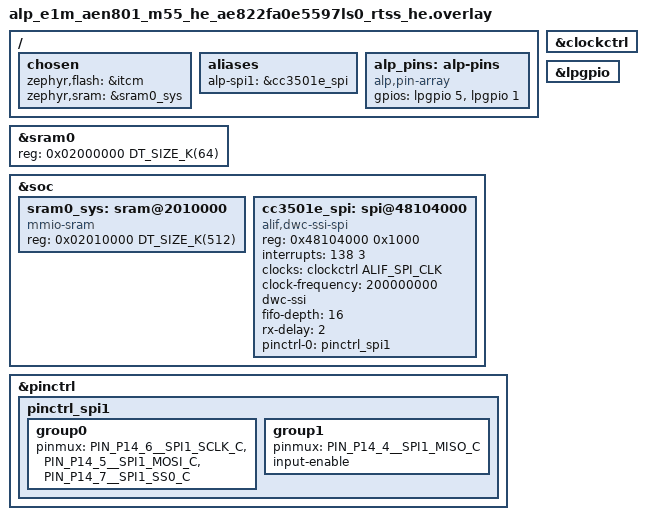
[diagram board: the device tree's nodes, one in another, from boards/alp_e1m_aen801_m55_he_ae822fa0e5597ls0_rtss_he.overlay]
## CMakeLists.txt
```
# SPDX-License-Identifier: Apache-2.0
#
# aen-cc3501e-connect-twice-probe -- tests whether a station-never-associated
# WIFI_DISCONNECT clears the CC3501E vendor SDK's WLAN_IF_DISCONNECT_IN_
# PROGRESS bit (#2035). See src/main.c for the full hypothesis and evidence
# chain.
#
# Standalone Zephyr app (no alp_project.py board.yaml flow), same shape as
# its siblings aen-cc3501e-command-sweep / aen-cc3501e-socket-throughput:
# build with
#   ZEPHYR_BASE=<zephyr-base> west build \
#     -b alp_e1m_aen801_m55_he/ae822fa0e5597ls0/rtss_he <this-dir> -- \
#     "-DEXTRA_ZEPHYR_MODULES=<alp-sdk>;<hal_alif>"
# Zephyr applies boards/<fully-qualified-board>.overlay by itself.

cmake_minimum_required(VERSION 3.20)

find_package(Zephyr REQUIRED HINTS $ENV{ZEPHYR_BASE})
project(aen_cc3501e_connect_twice_probe LANGUAGES C)

target_sources(app PRIVATE src/main.c)
# The SoM bring-up TEMPLATE (see its own header comment): opens the
# inter-chip SPI1 bridge + WIFI_EN/nRESET, enables the LP-pad output
# drivers pinctrl does not reach, binds the READY line, and runs the
# power + reset sequence. Copied verbatim from aen-cc3501e-command-sweep --
# byte-identical to the copies in every other aen-cc3501e-* sibling, same
# reasoning: a copyable template, not a cross-example reach-in.
target_sources(app PRIVATE src/cc3501e_bridge.c)
```

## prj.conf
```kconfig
# SPDX-License-Identifier: Apache-2.0
#
# Bench config for the CC3501E connect-twice probe on the E1M-AEN801 (Alif
# Ensemble E8, M55-HE). See src/main.c for the hypothesis this app tests.

# --- Console -----------------------------------------------------------------
# Console: Alp UART console -- E1M edge UART0 (Alif UART5, P3_4/P3_5, 115200
# 8N1, NS16550), the E1M-AEN801 carrier console. The board _defconfig already
# selects it; set explicitly here so the app is self-describing.
CONFIG_SERIAL=y
CONFIG_CONSOLE=y
CONFIG_UART_CONSOLE=y
CONFIG_UART_INTERRUPT_DRIVEN=y
# Serial-less bench? Comment the four lines above and uncomment these to read
# 'ram_console_buf' over SWD instead -- the same toggle every sibling AEN
# bench app documents (see aen-rtc-tick-probe's prj.conf for the fuller note):
# CONFIG_RAM_CONSOLE=y
# CONFIG_RAM_CONSOLE_BUFFER_SIZE=4096
# CONFIG_UART_CONSOLE=n
CONFIG_PRINTK=y

# --- CC3501E bridge (SPI1 + WIFI_EN/nRESET/READY GPIOs) -----------------------
# The host-side chip driver (chips/cc3501e/*.c) plus the two peripheral
# classes it rides on: SPI for the inter-chip link (bus 1 -> the alp-spi1
# alias this app's overlay adds) and GPIO for WIFI_EN / nRESET / READY.
# Kconfig already enforces `depends on SPI && GPIO`; both are set explicitly
# here because this app has no board.yaml `peripherals:` block to generate
# them -- it is a standalone Zephyr app (see scripts/gen_example_alp_conf.py), same as its
# aen-cc3501e-* siblings. CONFIG_ALP_SDK_CHIP_CC3501E pulls in every
# chips/cc3501e/*.c TU (wifi/sockets/ble/gpio/spi/camera/power/ota/events),
# so this app can call cc3501e_wifi_scan()/cc3501e_wifi_connect()/
# cc3501e_wifi_status()/cc3501e_wifi_disconnect() directly with no further
# Kconfig -- it never routes through the portable <alp/wifi.h> backend
# (CONFIG_ALP_SDK_WIFI_CC3501E), which attaches a DIFFERENT set of TUs this
# app has no use for.
CONFIG_SPI=y
CONFIG_GPIO=y
CONFIG_ALP_SDK=y
CONFIG_ALP_SDK_CHIP_CC3501E=y

# CONFIG_ALP_SDK=y above defaults CONFIG_ALP_SDK_CONSOLE (zephyr/kconfigs/
# core.kconfig) to `y`, which `select`s CONFIG_SHELL -- pulling a `uart:~$`
# shell prompt into the middle of this app's own transcript. This app never
# registers a shell command and never uses the `alp` console tree, so turn
# the console off explicitly rather than let its default drag the shell in
# unasked.
CONFIG_ALP_SDK_CONSOLE=n

# main()'s own cc3501e_t bridge handle (~32 KB, embeds several
# ALP_CC3501E_MAX_PAYLOAD scratch buffers) is STATIC in src/main.c, not
# automatic -- see that file's own header for why that discipline is
# load-bearing here, not optional: a sibling app in this tree died on its own
# prologue for exactly the mistake this app avoids by construction. 4096
# matches every other aen-cc3501e-* sibling that calls this driver with the
# same static discipline and carries no bulk sweep buffers of its own.
CONFIG_MAIN_STACK_SIZE=4096

# Logging ON, deliberately -- a desynced SPI link reports its decisive fault
# via LOG_ERR in the upstream DesignWare SPI driver, and this app is a bench
# diagnostic, not a shipping image. LOG_MODE_MINIMAL keeps it deferred-free.
CONFIG_LOG=y
CONFIG_LOG_MODE_MINIMAL=y

# --- Memory/cache: MATCH aen-cc3501e-command-sweep, not just its pin config --
# CONFIG_DCACHE=n for the SoC-wide reason every AEN801 bench app carries it
# (scripts/bench/aen/aen-bench-shared.conf's own header: "the E8 D-cache
# maintenance loop hangs on this silicon"), AND because this app's PING /
# WIFI_STATUS reads ride the SAME SPI1 link every other AEN801 CC3501E bench
# app measures -- see the app overlay's own header for the matching
# zephyr,sram retarget this depends on.
CONFIG_DCACHE=n
```

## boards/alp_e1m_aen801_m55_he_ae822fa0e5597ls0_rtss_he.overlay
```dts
/*
 * Copyright (c) 2026 Alp Lab AB
 * SPDX-License-Identifier: Apache-2.0
 *
 * aen-cc3501e-connect-twice-probe -- app overlay for the E1M-AEN801 (Alif
 * Ensemble E8, M55-HE), bench RAM-run via J-Link.
 *
 * Byte-identical to aen-cc3501e-command-sweep's own overlay (itself
 * transcribed from aen-evk-demo's phase-8 overlay block -- see that file's
 * own header for the full derivation behind every value here), including
 * the SRAM0 system-RAM placement and CONFIG_DCACHE=n pairing this app does
 * NOT itself need for a throughput reason (it runs no bulk sweep) but keeps
 * anyway: this app's PING and WIFI_STATUS reads ride the identical SPI1
 * link every other AEN801 CC3501E bench app measures, and a
 * faster-than-intended cache/DTCM path would risk a DIFFERENT link timing
 * than the one every sibling's bench evidence was gathered against. Trimmed
 * to exactly what the bridge needs: the SoM-internal Alif <-> CC3501E link
 * (SPI1 hardware SS0, the LP-GPIO island carrying WIFI_EN/nRESET, and the
 * READY input) plus the mandatory bench ITCM retarget. None of
 * aen-evk-demo's other thirteen phases' OWN hardware (PWM LED, SD, Ethernet,
 * I2S/PDM, JPEG) is declared here -- this app touches none of it, and
 * carrying it would only risk a pad conflict with the bridge pins.
 */
#include <zephyr/dt-bindings/pinctrl/alif-ensemble-pinctrl.h>
#include <zephyr/dt-bindings/gpio/gpio.h>

/*
 * ============================================================================
 * SYSTEM-RAM PLACEMENT -- MATCHES aen-evk-demo's phase 8, deliberately
 * ============================================================================
 *
 * This app trims aen-evk-demo's overlay down to exactly the SoM-internal
 * CC3501E bridge (see the block below) -- EXCEPT for this one piece, which
 * it keeps even though nothing else here needs it.
 *
 * aen-evk-demo's own overlay (see ITS header for the full derivation, which
 * this app does not repeat) documents that phase 8's SPI1 FIFO refill --
 * the SAME link this app's Part 2 clocks bulk STREAM_WRITE / SPI1_TRANSFER
 * frames over -- is the one phase sensitive to cache-on vs cache-off timing
 * on this silicon: a DesignWare SSI master that underruns its TX FIFO
 * deasserts its own chip-select mid-frame, and the demo runs from uncached
 * global SRAM0 with CONFIG_DCACHE=n (see prj.conf) rather than the M55's
 * tightly-coupled DTCM specifically to keep that FIFO-refill loop on the
 * same timing this silicon was bench-validated against.
 *
 * A throughput measurement over that link cannot run FASTER than the demo's
 * on precisely the axis the demo's own comment calls out -- that would not
 * be a number anyone else's AEN801 bench run could be compared against, it
 * would be measuring a different link. So this app carries the same
 * retarget, even though (unlike the demo) it has no Ethernet DMA rings or
 * JPEG buffers that need SRAM0 for their own reasons -- one disjoint 512 KiB
 * window is more than this app's own footprint needs, but a narrower
 * carve-out would only add a second constant to keep in sync with the demo
 * for no behavioural benefit.
 */
&sram0 {
	reg = <0x02000000 DT_SIZE_K(64)>;
};

&soc {
	/* Plain "mmio-sram", NOT "zephyr,memory-region" -- see aen-evk-demo's
	 * overlay for why a second memory-region-compatible node here would
	 * alias the linker region instead of extending it. */
	sram0_sys: sram@2010000 {
		compatible = "mmio-sram";
		reg = <0x02010000 DT_SIZE_K(512)>;
	};
};

/*
 * MANDATORY bench RAM-run retarget: run from ITCM so J-Link can loadbin+run
 * without programming MRAM, and drop the MCUboot code-partition fixup.
 * PATH-REFERENCE form (&itcm), NOT the <&itcm> phandle-array form -- the
 * phandle-array form yields CONFIG_FLASH_SIZE=0 and the image overflows the
 * (empty) FLASH region at link time. System RAM (zephyr,sram) is retargeted
 * separately, to &sram0_sys above -- see that block's header.
 */
/ {
	chosen {
		zephyr,flash = &itcm;
		/delete-property/ zephyr,code-partition;
		zephyr,sram = &sram0_sys;
	};
};

/*
 * ============================================================================
 * The SoM-internal Alif <-> CC3501E Wi-Fi/BLE bridge
 * ============================================================================
 *
 *     net          Alif pad       dir   CC3501E pad
 *     ----------   ------------   ---   ---------------------
 *     WIFI_EN      P15_5          out   (supply gate)
 *     E_WIFI.NRST  P15_1_FLEX     out   (reset)
 *     SPI1.SCK     P14_6          out   GPIO_27 (CC35 SPI0 slave)
 *     SPI1.MOSI    P14_5          out   GPIO_28
 *     SPI1.MISO    P14_4          in    GPIO_29
 *     SPI1.SS0     P14_7          out   CC35 SPI0 CSN
 *
 * READY (CC35 GPIO_17) is deliberately left off this table: on the R2
 * module this app targets it is NOT wired to Alif P2_6 -- P2_6 is E1M pad
 * AH7 / I2S1_SCLK (the EVK's Arduino CK_RST), a DIFFERENT net from GPIO_17
 * / E1M pad G3.  See the P2_6 comment further down and
 * chips/cc3501e/cc3501e_core.c's cc3501e_reply_gate() comment for the bench
 * evidence and how a board that genuinely wires it can opt in.
 *
 * SoM-INTERNAL fact (metadata/e1m_modules/aen/inter-chip.tsv), not an E1M
 * edge pad -- hence an app overlay, not the board tree.
 */
&pinctrl {
	/*
	 * SPI1 master on P14_6 (SCK) / P14_5 (MOSI) / P14_4 (MISO), plus the
	 * hardware SS0 chip-select on P14_7. SS0 is the dwc-ssi peripheral's
	 * OWN select -- not a GPIO bodge, not CS-less, not static-low: the
	 * master asserts and deasserts it per transfer, which is exactly what
	 * frames each phase of the bridge's request/reply exchange. Do NOT
	 * add cs-gpios here; that installs a software CS and breaks the
	 * framing the firmware side is built around.
	 *
	 * input-enable on MISO because on this SoC a pad's INPUT BUFFER is a
	 * PADCTRL bit that only pinctrl sets -- without it the pad never
	 * senses what the slave drives.
	 */
	pinctrl_spi1: pinctrl_spi1 {
		group0 {
			pinmux = <PIN_P14_6__SPI1_SCLK_C>, <PIN_P14_5__SPI1_MOSI_C>,
				 <PIN_P14_7__SPI1_SS0_C>;
		};
		group1 {
			pinmux = <PIN_P14_4__SPI1_MISO_C>;
			input-enable;
		};

	};
};

/* P2_6 (E1M AH7 / I2S1_SCLK) is NOT the CC3501E READY net on the R2 module this
 * bridge targets -- it is E1M pad AH7 / I2S1_SCLK, which the E1M EVK
 * carrier repurposes as the Arduino header's CK_RST (metadata/boards/
 * e1m-evk.yaml); the real READY net lands on E1M pad G3 / IO16 instead
 * (metadata/e1m_modules/aen/from-cc3501e.tsv). This app therefore does not
 * mux or input-enable P2_6, and does not wire fw->ready_pin -- see
 * src/cc3501e_bridge.c and chips/cc3501e/cc3501e_core.c's cc3501e_reply_gate()
 * comment. A board (or a hand-reworked r1 unit) that genuinely wires GPIO17
 * to P2_6 can opt back in: add a pinctrl group muxing PIN_P2_6__GPIO with
 * input-enable (applied inside pinctrl_spi1's single init pass, not a
 * standalone runtime one -- a second pinctrl pass after SPI1 is up killed
 * the bridge on silicon, aen-evk-demo bench-measured), enable &gpio2, add
 * an alp_pins entry for it, and set fw->ready_pin in
 * cc3501e_bridge_bringup().

/*
 * DWC_ssi SPI1 (AHB) -- the on-SoM CC3501E inter-chip link. Deliberately not
 * in ensemble_e8_peripherals.dtsi (which declares only the customer-facing
 * edge SPI0), so the consuming app declares it. reg 0x48104000 = the SPI1
 * base (+0x1000 per instance from spi0's 0x48103000).
 *
 * clock-frequency is REQUIRED, not decorative: without it spi_dw_alif's
 * configure takes the clock-control path, which fails -EINVAL for the
 * gateless dummy ALIF_SPI_CLK, and every transceive then returns
 * ALP_ERR_INVAL at zero SCLK. 200 MHz is the real SSI functional clock (E8
 * HWRM); BAUDR = clock-frequency / freq_hz, and cc3501e_bridge.h asks for
 * 25 MHz = /8.
 *
 * rx-delay: NOT what clocks the link -- src/cc3501e_bridge.c pokes
 * 0x48104000+0xf0 with CC3501E_BRIDGE_RX_SAMPLE_DLY right after
 * alp_spi_open() returns, and that constant (silicon-measured, see that
 * file's header) is what the bridge actually runs at. Kept at <2> anyway
 * because the poke is wrapped in `#if CC3501E_BRIDGE_RX_SAMPLE_DLY > 0` --
 * setting the constant to 0 does not mean "no delay", it means this
 * property is what survives.
 */
&clockctrl {
	status = "okay";
};

&soc {
	cc3501e_spi: spi@48104000 {
		compatible = "alif,dwc-ssi-spi";
		#address-cells = <1>;
		#size-cells = <0>;
		reg = <0x48104000 0x1000>;
		interrupts = <138 3>; /* BENCH-TBD: confirm SPI1 IRQ, same as aen-evk-demo */
		clocks = <&clockctrl ALIF_SPI_CLK>;
		clock-frequency = <200000000>;
		dwc-ssi;
		fifo-depth = <16>;
		rx-delay = <2>;
		pinctrl-0 = <&pinctrl_spi1>;
		pinctrl-names = "default";
		status = "okay";
	};
};

/*
 * The LP-GPIO island carries WIFI_EN (P15_5) and E_WIFI.NRST (P15_1_FLEX).
 * No pinctrl group is needed for their mux: P15_x function 0 -- the reset
 * default -- already IS LPGPIO. Turning the pads' OUTPUT DRIVERS on is a
 * separate matter and not a devicetree fact at all; see the raw PADCTRL
 * write in src/cc3501e_bridge.c and the comment above it.
 */
&lpgpio {
	status = "okay";
};

/ {
	aliases {
		/* bus_id 1 in alp_spi_open() -> this controller. */
		alp-spi1 = &cc3501e_spi;
	};

	/*
	 * Compact 2-entry control array for the SoM-internal CC3501E control
	 * nets, in the order cc3501e_bridge.h's CC3501E_BRIDGE_PIN_* indices
	 * expect. These are NOT E1M edge pads, so this app does not use the
	 * 52-slot positional E1M map; a production board file appends
	 * SoM-internal control nets after the E1M pad slots. No READY entry
	 * here -- see the P2_6 comment above &gpio2's removal further up.
	 *
	 * There must be exactly ONE "alp,pin-array" node in the tree -- a
	 * second one broke pin resolution outright on the aen-evk-demo bench
	 * (2026-08-26): the bridge failed as if WIFI_EN were absent, which
	 * reads like a hardware fault and is not one.
	 */
	alp_pins: alp-pins {
		compatible = "alp,pin-array";
		gpios = <&lpgpio 5 GPIO_ACTIVE_HIGH>, /* [0] WIFI_EN     (P15_5)      */
			<&lpgpio 1 GPIO_ACTIVE_HIGH>; /* [1] E_WIFI.NRST (P15_1_FLEX) */
	};
};
```

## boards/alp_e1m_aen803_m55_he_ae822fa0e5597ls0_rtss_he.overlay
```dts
/*
 * Copyright (c) 2026 Alp Lab AB
 * SPDX-License-Identifier: Apache-2.0
 *
 * aen-cc3501e-connect-twice-probe -- app overlay for the E1M-AEN803 (Alif
 * Ensemble E8, M55-HE), bench RAM-run via J-Link.
 *
 * Byte-identical to aen-cc3501e-command-sweep's own overlay (itself
 * transcribed from aen-evk-demo's phase-8 overlay block -- see that file's
 * own header for the full derivation behind every value here), including
 * the SRAM0 system-RAM placement and CONFIG_DCACHE=n pairing this app does
 * NOT itself need for a throughput reason (it runs no bulk sweep) but keeps
 * anyway: this app's PING and WIFI_STATUS reads ride the identical SPI1
 * link every other AEN803 CC3501E bench app measures, and a
 * faster-than-intended cache/DTCM path would risk a DIFFERENT link timing
 * than the one every sibling's bench evidence was gathered against. Trimmed
 * to exactly what the bridge needs: the SoM-internal Alif <-> CC3501E link
 * (SPI1 hardware SS0, the LP-GPIO island carrying WIFI_EN/nRESET, and the
 * READY input) plus the mandatory bench ITCM retarget. None of
 * aen-evk-demo's other thirteen phases' OWN hardware (PWM LED, SD, Ethernet,
 * I2S/PDM, JPEG) is declared here -- this app touches none of it, and
 * carrying it would only risk a pad conflict with the bridge pins.
 */
#include <zephyr/dt-bindings/pinctrl/alif-ensemble-pinctrl.h>
#include <zephyr/dt-bindings/gpio/gpio.h>

/*
 * ============================================================================
 * SYSTEM-RAM PLACEMENT -- MATCHES aen-evk-demo's phase 8, deliberately
 * ============================================================================
 *
 * This app trims aen-evk-demo's overlay down to exactly the SoM-internal
 * CC3501E bridge (see the block below) -- EXCEPT for this one piece, which
 * it keeps even though nothing else here needs it.
 *
 * aen-evk-demo's own overlay (see ITS header for the full derivation, which
 * this app does not repeat) documents that phase 8's SPI1 FIFO refill --
 * the SAME link this app's Part 2 clocks bulk STREAM_WRITE / SPI1_TRANSFER
 * frames over -- is the one phase sensitive to cache-on vs cache-off timing
 * on this silicon: a DesignWare SSI master that underruns its TX FIFO
 * deasserts its own chip-select mid-frame, and the demo runs from uncached
 * global SRAM0 with CONFIG_DCACHE=n (see prj.conf) rather than the M55's
 * tightly-coupled DTCM specifically to keep that FIFO-refill loop on the
 * same timing this silicon was bench-validated against.
 *
 * A throughput measurement over that link cannot run FASTER than the demo's
 * on precisely the axis the demo's own comment calls out -- that would not
 * be a number anyone else's AEN803 bench run could be compared against, it
 * would be measuring a different link. So this app carries the same
 * retarget, even though (unlike the demo) it has no Ethernet DMA rings or
 * JPEG buffers that need SRAM0 for their own reasons -- one disjoint 512 KiB
 * window is more than this app's own footprint needs, but a narrower
 * carve-out would only add a second constant to keep in sync with the demo
 * for no behavioural benefit.
 */
&sram0 {
	reg = <0x02000000 DT_SIZE_K(64)>;
};

&soc {
	/* Plain "mmio-sram", NOT "zephyr,memory-region" -- see aen-evk-demo's
	 * overlay for why a second memory-region-compatible node here would
	 * alias the linker region instead of extending it. */
	sram0_sys: sram@2010000 {
		compatible = "mmio-sram";
		reg = <0x02010000 DT_SIZE_K(512)>;
	};
};

/*
 * MANDATORY bench RAM-run retarget: run from ITCM so J-Link can loadbin+run
 * without programming MRAM, and drop the MCUboot code-partition fixup.
 * PATH-REFERENCE form (&itcm), NOT the <&itcm> phandle-array form -- the
 * phandle-array form yields CONFIG_FLASH_SIZE=0 and the image overflows the
 * (empty) FLASH region at link time. System RAM (zephyr,sram) is retargeted
 * separately, to &sram0_sys above -- see that block's header.
 */
/ {
	chosen {
		zephyr,flash = &itcm;
		/delete-property/ zephyr,code-partition;
		zephyr,sram = &sram0_sys;
	};
};

/*
 * ============================================================================
 * The SoM-internal Alif <-> CC3501E Wi-Fi/BLE bridge
 * ============================================================================
 *
 *     net          Alif pad       dir   CC3501E pad
 *     ----------   ------------   ---   ---------------------
 *     WIFI_EN      P15_5          out   (supply gate)
 *     E_WIFI.NRST  P15_1_FLEX     out   (reset)
 *     SPI1.SCK     P14_6          out   GPIO_27 (CC35 SPI0 slave)
 *     SPI1.MOSI    P14_5          out   GPIO_28
 *     SPI1.MISO    P14_4          in    GPIO_29
 *     SPI1.SS0     P14_7          out   CC35 SPI0 CSN
 *
 * READY (CC35 GPIO_17) is deliberately left off this table: on the R2
 * module this app targets it is NOT wired to Alif P2_6 -- P2_6 is E1M pad
 * AH7 / I2S1_SCLK (the EVK's Arduino CK_RST), a DIFFERENT net from GPIO_17
 * / E1M pad G3.  See the P2_6 comment further down and
 * chips/cc3501e/cc3501e_core.c's cc3501e_reply_gate() comment for the bench
 * evidence and how a board that genuinely wires it can opt in.
 *
 * SoM-INTERNAL fact (metadata/e1m_modules/aen/inter-chip.tsv), not an E1M
 * edge pad -- hence an app overlay, not the board tree.
 */
&pinctrl {
	/*
	 * SPI1 master on P14_6 (SCK) / P14_5 (MOSI) / P14_4 (MISO), plus the
	 * hardware SS0 chip-select on P14_7. SS0 is the dwc-ssi peripheral's
	 * OWN select -- not a GPIO bodge, not CS-less, not static-low: the
	 * master asserts and deasserts it per transfer, which is exactly what
	 * frames each phase of the bridge's request/reply exchange. Do NOT
	 * add cs-gpios here; that installs a software CS and breaks the
	 * framing the firmware side is built around.
	 *
	 * input-enable on MISO because on this SoC a pad's INPUT BUFFER is a
	 * PADCTRL bit that only pinctrl sets -- without it the pad never
	 * senses what the slave drives.
	 */
	pinctrl_spi1: pinctrl_spi1 {
		group0 {
			pinmux = <PIN_P14_6__SPI1_SCLK_C>, <PIN_P14_5__SPI1_MOSI_C>,
				 <PIN_P14_7__SPI1_SS0_C>;
		};
		group1 {
			pinmux = <PIN_P14_4__SPI1_MISO_C>;
			input-enable;
		};

	};
};

/* P2_6 (E1M AH7 / I2S1_SCLK) is NOT the CC3501E READY net on the R2 module this
 * bridge targets -- it is E1M pad AH7 / I2S1_SCLK, which the E1M EVK
 * carrier repurposes as the Arduino header's CK_RST (metadata/boards/
 * e1m-evk.yaml); the real READY net lands on E1M pad G3 / IO16 instead
 * (metadata/e1m_modules/aen/from-cc3501e.tsv). This app therefore does not
 * mux or input-enable P2_6, and does not wire fw->ready_pin -- see
 * src/cc3501e_bridge.c and chips/cc3501e/cc3501e_core.c's cc3501e_reply_gate()
 * comment. A board (or a hand-reworked r1 unit) that genuinely wires GPIO17
 * to P2_6 can opt back in: add a pinctrl group muxing PIN_P2_6__GPIO with
 * input-enable (applied inside pinctrl_spi1's single init pass, not a
 * standalone runtime one -- a second pinctrl pass after SPI1 is up killed
 * the bridge on silicon, aen-evk-demo bench-measured), enable &gpio2, add
 * an alp_pins entry for it, and set fw->ready_pin in
 * cc3501e_bridge_bringup().

/*
 * DWC_ssi SPI1 (AHB) -- the on-SoM CC3501E inter-chip link. Deliberately not
 * in ensemble_e8_peripherals.dtsi (which declares only the customer-facing
 * edge SPI0), so the consuming app declares it. reg 0x48104000 = the SPI1
 * base (+0x1000 per instance from spi0's 0x48103000).
 *
 * clock-frequency is REQUIRED, not decorative: without it spi_dw_alif's
 * configure takes the clock-control path, which fails -EINVAL for the
 * gateless dummy ALIF_SPI_CLK, and every transceive then returns
 * ALP_ERR_INVAL at zero SCLK. 200 MHz is the real SSI functional clock (E8
 * HWRM); BAUDR = clock-frequency / freq_hz, and cc3501e_bridge.h asks for
 * 25 MHz = /8.
 *
 * rx-delay: NOT what clocks the link -- src/cc3501e_bridge.c pokes
 * 0x48104000+0xf0 with CC3501E_BRIDGE_RX_SAMPLE_DLY right after
 * alp_spi_open() returns, and that constant (silicon-measured, see that
 * file's header) is what the bridge actually runs at. Kept at <2> anyway
 * because the poke is wrapped in `#if CC3501E_BRIDGE_RX_SAMPLE_DLY > 0` --
 * setting the constant to 0 does not mean "no delay", it means this
 * property is what survives.
 */
&clockctrl {
	status = "okay";
};

&soc {
	cc3501e_spi: spi@48104000 {
		compatible = "alif,dwc-ssi-spi";
		#address-cells = <1>;
		#size-cells = <0>;
		reg = <0x48104000 0x1000>;
		interrupts = <138 3>; /* BENCH-TBD: confirm SPI1 IRQ, same as aen-evk-demo */
		clocks = <&clockctrl ALIF_SPI_CLK>;
		clock-frequency = <200000000>;
		dwc-ssi;
		fifo-depth = <16>;
		rx-delay = <2>;
		pinctrl-0 = <&pinctrl_spi1>;
		pinctrl-names = "default";
		status = "okay";
	};
};

/*
 * The LP-GPIO island carries WIFI_EN (P15_5) and E_WIFI.NRST (P15_1_FLEX).
 * No pinctrl group is needed for their mux: P15_x function 0 -- the reset
 * default -- already IS LPGPIO. Turning the pads' OUTPUT DRIVERS on is a
 * separate matter and not a devicetree fact at all; see the raw PADCTRL
 * write in src/cc3501e_bridge.c and the comment above it.
 */
&lpgpio {
	status = "okay";
};

/ {
	aliases {
		/* bus_id 1 in alp_spi_open() -> this controller. */
		alp-spi1 = &cc3501e_spi;
	};

	/*
	 * Compact 2-entry control array for the SoM-internal CC3501E control
	 * nets, in the order cc3501e_bridge.h's CC3501E_BRIDGE_PIN_* indices
	 * expect. These are NOT E1M edge pads, so this app does not use the
	 * 52-slot positional E1M map; a production board file appends
	 * SoM-internal control nets after the E1M pad slots. No READY entry
	 * here -- see the P2_6 comment above &gpio2's removal further up.
	 *
	 * There must be exactly ONE "alp,pin-array" node in the tree -- a
	 * second one broke pin resolution outright on the aen-evk-demo bench
	 * (2026-08-26): the bridge failed as if WIFI_EN were absent, which
	 * reads like a hardware fault and is not one.
	 */
	alp_pins: alp-pins {
		compatible = "alp,pin-array";
		gpios = <&lpgpio 5 GPIO_ACTIVE_HIGH>, /* [0] WIFI_EN     (P15_5)      */
			<&lpgpio 1 GPIO_ACTIVE_HIGH>; /* [1] E_WIFI.NRST (P15_1_FLEX) */
	};
};
```

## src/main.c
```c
/*
 * Copyright (c) 2026 Alp Lab AB
 * SPDX-License-Identifier: Apache-2.0
 *
 * aen-cc3501e-connect-twice-probe -- tests whether a WIFI_DISCONNECT issued
 * against a station that never associated clears the CC3501E vendor SDK's
 * WLAN_IF_DISCONNECT_IN_PROGRESS bit, for the E1M-AEN801 (Alif Ensemble E8,
 * M55-HE), bench RAM-run via J-Link.
 *
 * THE CHAIN THIS APP TESTS
 * ---------------------------
 * Read from the TI vendor SDK sources directly
 * (source/ti/net/wifi_stack/app_entry/wlan_if.c and .../cme/cme.c,
 * simplelink_wifi_sdk_10_10_01_08), not inferred:
 *
 *   1. Wlan_Disconnect() calls set_cond_in_process_wlan_discconnect(1),
 *      which sets WLAN_IF_DISCONNECT_IN_PROGRESS in the SDK's own
 *      g_oper_bitmap.
 *   2. On the STATION branch (the `default:` case of Wlan_Disconnect()'s
 *      switch, which is what a plain STA disconnect always takes) it
 *      returns WITHOUT clearing that bit -- only the AP branch and the
 *      `fail:` label clear it inline. Read the function yourself before
 *      touching this file: the station path's own `else { return ret; }`
 *      is the whole defect surface.
 *   3. The only other place that clears it is the WLAN_EVENT_DISCONNECT
 *      handler (cme.c, wlanDispatcherSendEvent(WLAN_EVENT_DISCONNECT, ...)).
 *   4. Wlan_Connect() gates on the SAME bitmap via
 *      set_cond_in_process_wlan_connect() -> is_wlan_oper_in_progress(),
 *      whose allow-mask for CONNECT is
 *      ROLE_UP_AP | ROLE_DOWN_AP | SET | GET | GET_EXCLUDE | SET_EXCLUDE.
 *      WLAN_IF_DISCONNECT_IN_PROGRESS is NOT in that mask.
 *   5. So while that bit stays set, every Wlan_Connect returns
 *      RET_OPER_IN_PROGRESS immediately -- which the bridge firmware maps
 *      to ALP_CC3501E_WIFI_FAIL_KICK.
 *
 * THE ONE UNPROVEN LINK -- and the only thing this app exists to test:
 * whether the supplicant emits WLAN_EVENT_DISCONNECT when asked to
 * disconnect a station that never associated. If it does, the bit clears
 * (mechanism 3 above fires) and none of this bites. If it does NOT, the bit
 * sticks for the rest of the session and every later connect dies at the
 * kick (mechanism 5).
 *
 * WHY THIS APP CAN OBSERVE THAT WITHOUT READING FIRMWARE STATE DIRECTLY:
 * cc3501e_wifi_connect() (chips/cc3501e/cc3501e_wifi.c) already issues a
 * WIFI_DISCONNECT at ENTRY whenever the WIFI_STATUS latch reads
 * CONN_FAILED from a previous attempt -- see that function's own #1435
 * comment. THAT disconnect is itself the call that would set the bit in
 * the first place if attempt one never associated. Attempt two's entry
 * clear is therefore exactly the real path this app exists to exercise --
 * do NOT try to bypass it or call cc3501e_wifi_disconnect() directly
 * around it; the whole point is to let cc3501e_wifi_connect()'s own,
 * already-shipped, entry-clear logic run twice back to back.
 *
 * WHY SCAN FIRST -- load-bearing, not decoration
 * --------------------------------------------------
 * On the scan-first ordering the link survives a failed connect --
 * measured 2 of 2 in a firmware-side A/B, NOT by any app in this tree --
 * no example here issues a scan before a connect, so do not go looking
 * for the run that produced it. Connect-first wedges it and nothing
 * afterwards can be
 * read. Without the scan this app cannot report anything at all: STEP 3
 * below runs cc3501e_wifi_scan() and prints the record count BEFORE either
 * connect attempt, precisely because skipping it would risk losing the
 * WIFI_STATUS reads that are this app's entire payload.
 *
 * THE PREDICTION -- so the operator does not have to hold it in their head
 * ------------------------------------------------------------------------
 * If attempt one reports FAIL_TIMEOUT and attempt two reports FAIL_KICK,
 * the bit sticks and the hypothesis is CONFIRMED. If both report the SAME
 * reason, it does not stick and the hypothesis is DEAD. If attempt one
 * SUCCEEDS, this run says nothing about any of this -- there was no
 * failure to leave the bit set behind in the first place. STEP 6 below
 * prints exactly this and nothing more; the reasoning belongs to whoever
 * reads the transcript, not to this app.
 *
 * SECURITY VALUE ON THE WIRE -- do not mix the two encodings up
 * --------------------------------------------------------------
 * cc3501e_wifi_connect()'s own `sec_type` parameter goes on the wire as
 * <alp/protocol/cc3501e.h>'s alp_cc3501e_wifi_connect_t::security field:
 * 0 = open, 1 = WPA2-PSK, 2 = WPA3-SAE (CC3501E_WIFI_CONNECT_SEC_OPEN /
 * _WPA2_PSK / _WPA3_SAE in <alp/chips/cc3501e/wifi.h>). This is a DIFFERENT
 * encoding from the scan-RESULT security enum in that same header
 * (cc3501e_wifi_sec_t), where 1 means WEP -- this app never touches that
 * second enum (it only prints scan record COUNT, not per-record security),
 * but a reader porting this pattern elsewhere should not conflate the two.
 *
 * CREDENTIALS -- never committed
 * ---------------------------------
 * Build-time defines, empty defaults, this app's OWN macro prefix
 * (CONNTWICE_*) so a combined build cannot collide with
 * aen-cc3501e-companion-tour's TOUR_*, aen-cc3501e-socket-throughput's
 * SOCKTP_*, aen-cc3501e-bringup's CC3501E_WIFI_*, or
 * aen-cc3501e-wedge-postmortem's WEDGEPM_*. No SSID or passphrase is
 * embedded anywhere in this file. When CONNTWICE_WIFI_SSID is empty, main()
 * says so and stops before either connect attempt runs -- there would be
 * nothing to disconnect and nothing to observe.
 *
 * WHAT THIS APP NEVER DOES
 * ---------------------------
 * Never OTA_*, never RESET, never a soft-AP -- the only opcodes this file
 * issues are WIFI_SCAN_START (via cc3501e_wifi_scan(), STEP 3),
 * WIFI_CONNECT_STA (via cc3501e_wifi_connect(), STEPs 4 and 5, which itself
 * issues WIFI_DISCONNECT at entry when required -- see above), and
 * WIFI_STATUS (via cc3501e_wifi_status(), read after each attempt). Never
 * runs hardware beyond the bench RAM-run this file's own header line names.
 *
 * Build target: alp_e1m_aen801_m55_he/ae822fa0e5597ls0/rtss_he -- same
 * overlay memory placement and CONFIG_DCACHE=n as
 * aen-cc3501e-command-sweep; see this app's README.md for the full west
 * build invocation and that sibling's overlay for why the memory placement
 * is load-bearing, not decorative.
 */

#include <stdbool.h>
#include <stdint.h>

#include <zephyr/kernel.h>

#include "alp/chips/cc3501e.h"
#include "cc3501e_bridge.h" /* cc3501e_bridge_bringup() -- the SoM bring-up template */

/*
 * ======================================================================
 * Tunables -- timeouts and the (build-time) Wi-Fi credentials the file
 * header above explains.
 * ======================================================================
 */

/* Same shape and reasoning as every aen-cc3501e-* sibling's own PING retry
 * loop (e.g. aen-cc3501e-socket-throughput's SOCKTP_PING_RETRIES): the
 * bring-up call already waited out its own boot budget once, so this loop
 * only absorbs residual ramp/boot jitter. */
#define CONNTWICE_PING_RETRIES 25u
#define CONNTWICE_PING_GAP_MS  200u

/* Floored internally to 20 s by cc3501e_wifi_scan() regardless (see that
 * function's own doc) -- this asks for a little more so the literal here
 * means what it says rather than being silently corrected, same reasoning
 * as aen-cc3501e-command-sweep's identical 25 s scan budget. */
#define CONNTWICE_SCAN_TIMEOUT_MS 25000u

/* Full connect budget, NOT a shortened one -- unlike
 * aen-cc3501e-wedge-postmortem's deliberately-shrunk WEDGEPM_CONNECT_
 * TIMEOUT_MS (that app wants to catch the link mid-wedge; this app wants
 * each attempt to reach a genuine TERMINAL WIFI_STATUS so the fail_reason
 * pair it reports is real, not an artifact of giving up early). Same
 * derivation as aen-cc3501e-socket-throughput's SOCKTP_CONNECT_TIMEOUT_MS:
 * the firmware's own worst case is a 10 s Wlan_RoleUp inside the connect body
 * (this image never calls cc3501e_hw_wifi_boot_start, so the first radio op of
 * a boot carries it) + 30 s L2 association + a 30 s DHCP-lease poll
 * (hal/ti/cc3501e_hw_ti_wifi.c) = 70 s, and the firmware documents 75000 ms
 * as the caller budget that clears it (alp-sdk#2079). A connect that gives
 * up early cannot tell a stuck disconnect bit from an impatient caller, and
 * telling those apart is the entire point of the app. */
#define CONNTWICE_CONNECT_TIMEOUT_MS 75000u

/*
 * Wi-Fi STA credentials for both connect attempts. DELIBERATELY EMPTY by
 * default -- never hardcode bench credentials in a public example. Set
 * them at build time WITHOUT editing this file, e.g.:
 *
 *   west build ... -- -DEXTRA_CFLAGS="-DCONNTWICE_WIFI_SSID=\\\"myssid\\\" \
 *                                     -DCONNTWICE_WIFI_PASS=\\\"mypass\\\""
 *
 * When CONNTWICE_WIFI_SSID is empty, main() prints one line saying so and
 * returns before STEP 3 (the scan) even runs -- there is nothing to
 * connect twice, so there is nothing for this app to observe.
 */
#ifndef CONNTWICE_WIFI_SSID
#define CONNTWICE_WIFI_SSID ""
#endif
#ifndef CONNTWICE_WIFI_PASS
#define CONNTWICE_WIFI_PASS ""
#endif
/* Security selector on the WIRE encoding: 0 = open, 1 = WPA2-PSK,
 * 2 = WPA3-SAE (CC3501E_WIFI_CONNECT_SEC_* in <alp/chips/cc3501e/wifi.h>) --
 * see the file header's SECURITY VALUE note for why this is NOT the same
 * numbering as the scan-result security enum. */
#ifndef CONNTWICE_WIFI_SECURITY
#define CONNTWICE_WIFI_SECURITY CC3501E_WIFI_CONNECT_SEC_WPA2_PSK
#endif

/** @brief Human name for an @ref alp_cc3501e_wifi_conn_state_t value. */
static const char *conntwice_state_name(uint8_t state)
{
	switch (state) {
	case ALP_CC3501E_WIFI_DISCONNECTED:
		return "DISCONNECTED";
	case ALP_CC3501E_WIFI_CONNECTING:
		return "CONNECTING";
	case ALP_CC3501E_WIFI_CONNECTED:
		return "CONNECTED";
	case ALP_CC3501E_WIFI_CONN_FAILED:
		return "CONN_FAILED";
	default:
		return "UNKNOWN";
	}
}

/** @brief Human name for an @ref alp_cc3501e_wifi_fail_t value. */
static const char *conntwice_fail_name(uint8_t fail_reason)
{
	switch (fail_reason) {
	case ALP_CC3501E_WIFI_FAIL_NONE:
		return "FAIL_NONE";
	case ALP_CC3501E_WIFI_FAIL_TIMEOUT:
		return "FAIL_TIMEOUT";
	case ALP_CC3501E_WIFI_FAIL_REJECTED:
		return "FAIL_REJECTED";
	case ALP_CC3501E_WIFI_FAIL_KICK:
		return "FAIL_KICK";
	default:
		return "UNKNOWN";
	}
}

/**
 * @brief Run one WIFI_CONNECT_STA attempt and report the terminal WIFI_STATUS.
 *
 * Deliberately does NOT return a bare @c alp_status_t from
 * cc3501e_wifi_connect() as this app's verdict -- that return code collapses
 * TIMEOUT vs REJECTED vs KICK into two bare error codes (see the file
 * header). The independent @ref cc3501e_wifi_status read after it is what
 * this app actually cares about.
 *
 * @param fw          Initialised bridge handle.
 * @param attempt_no  1 or 2, for the printed labels only.
 * @param status_out  Receives the decoded WIFI_STATUS snapshot (zeroed if
 *                     the status read itself failed).
 * @return The @ref cc3501e_wifi_status return code -- ALP_OK if @p status_out
 *         is valid, otherwise the status read's own error.
 */
static alp_status_t
conntwice_attempt(cc3501e_t *fw, unsigned attempt_no, alp_cc3501e_wifi_status_t *status_out)
{
	printk("\nSTEP %u: CONNECT attempt %u -> SSID \"%s\" (sec %u)...\n",
	       3u + attempt_no,
	       attempt_no,
	       CONNTWICE_WIFI_SSID,
	       (unsigned)CONNTWICE_WIFI_SECURITY);

	int64_t      t0 = k_uptime_get();
	alp_status_t rc = cc3501e_wifi_connect(fw,
	                                       CONNTWICE_WIFI_SSID,
	                                       (uint8_t)CONNTWICE_WIFI_SECURITY,
	                                       CONNTWICE_WIFI_PASS,
	                                       CONNTWICE_CONNECT_TIMEOUT_MS);
	int64_t      dt = k_uptime_get() - t0;
	printk("  cc3501e_wifi_connect() -> %d (elapsed_ms=%lld) -- this bare return code alone"
	       " collapses TIMEOUT/REJECTED/KICK; see WIFI_STATUS below for the real reason.\n",
	       (int)rc,
	       (long long)dt);

	alp_cc3501e_wifi_status_t st = { 0 };
	alp_status_t              sr = cc3501e_wifi_status(fw, &st);
	if (sr == ALP_OK) {
		printk("  WIFI_STATUS -> state=%u (%s)  fail_reason=%u (%s)\n",
		       (unsigned)st.state,
		       conntwice_state_name(st.state),
		       (unsigned)st.fail_reason,
		       conntwice_fail_name(st.fail_reason));
	} else {
		printk("  WIFI_STATUS read FAILED (rc=%d) -- state/fail_reason UNREAD for this"
		       " attempt.\n",
		       (int)sr);
	}
	if (status_out != NULL) {
		*status_out = st;
	}
	return sr;
}

/* ---------------------------------------------------------------------- */

int main(void)
{
	printk("\n=== AEN801 CC3501E connect-twice probe (#2035) ===\n");

	/*
	 * STATIC, explicitly zero-initialised cc3501e_t -- same discipline as
	 * every aen-cc3501e-* sibling, for the identical reason: this type
	 * embeds several ALP_CC3501E_MAX_PAYLOAD scratch buffers (~32 KB
	 * total). Declared automatic it asks main() for a multi-kilobyte
	 * stack frame, and Zephyr's stack-overflow check fires on the very
	 * first `sub sp` -- before this function's own first printk, so the
	 * app dies with no output at all and looks like a dead board. That is
	 * not hypothetical: it happened on the M55-HE 2026-09-10 and cost a
	 * bench run (see aen-cc3501e-handshake-probe's own prj.conf).
	 */
	static cc3501e_t fw = { 0 };

	/*
	 * ---------------------------------------------------------------
	 * STEP 1 -- bring the bridge up, byte-identical to aen-evk-demo
	 * phase 8 and every aen-cc3501e-* sibling (same
	 * src/cc3501e_bridge.{c,h} template, same overlay).
	 * ---------------------------------------------------------------
	 */
	alp_status_t rc = cc3501e_bridge_bringup(&fw);
	printk("STEP 1: bridge bring-up (WIFI_EN high, nRESET pulsed, SPI1 @ %u Hz) -> %d\n",
	       (unsigned)CC3501E_BRIDGE_SPI_FREQ_HZ,
	       (int)rc);
	if (rc != ALP_OK) {
		printk("  ** bring-up did NOT return ALP_OK -- nothing downstream of it can work."
		       " Stopping here. **\n");
		return 0;
	}

	/*
	 * ---------------------------------------------------------------
	 * STEP 2 -- confirm the link answers before spending a scan/connect
	 * budget on it. Same retry shape as aen-cc3501e-socket-throughput's
	 * own STEP 2.
	 * ---------------------------------------------------------------
	 */
	bool up = false;
	for (unsigned i = 0u; i < CONNTWICE_PING_RETRIES; i++) {
		if (cc3501e_ping(&fw) == ALP_OK) {
			printk("STEP 2: PING ok after %u attempt%s\n", i + 1u, (i == 0u) ? "" : "s");
			up = true;
			break;
		}
		k_msleep(CONNTWICE_PING_GAP_MS);
	}
	if (!up) {
		printk("STEP 2: PING never answered -- check WIFI_EN power, the SPI1 pinmux, and"
		       " that the CC3501E is running its firmware. Stopping here.\n");
		return 0;
	}

	if (CONNTWICE_WIFI_SSID[0] == '\0') {
		printk("\nNo SSID configured (CONNTWICE_WIFI_SSID empty -- set it at build time,"
		       " see this file's header). Nothing to connect twice, nothing to observe."
		       " Stopping here.\n");
		return 0;
	}

	/*
	 * ---------------------------------------------------------------
	 * STEP 3 -- scan FIRST. Load-bearing, not decoration: on the
	 * scan-first ordering the link survives a failed connect (measured,
	 * 2 of 2); connect-first wedges it and nothing afterwards can be
	 * read. See the file header's WHY SCAN FIRST section.
	 * ---------------------------------------------------------------
	 */
	static cc3501e_scan_record_t scan_records[8];
	size_t                       scan_count = 0u;
	alp_status_t                 scan_rc    = cc3501e_wifi_scan(
	    &fw, scan_records, ARRAY_SIZE(scan_records), &scan_count, CONNTWICE_SCAN_TIMEOUT_MS);
	printk("STEP 3: WIFI_SCAN_START -> %d, %u record(s) (capped at %u)\n",
	       (int)scan_rc,
	       (unsigned)scan_count,
	       (unsigned)ARRAY_SIZE(scan_records));
	if (scan_rc != ALP_OK) {
		printk("  ** scan did not return ALP_OK -- proceeding to the connect attempts"
		       " anyway (this app never stops early on a failed step: a failed step's"
		       " own outcome is data), but the scan-first protection this app relies on"
		       " may not have run to completion. **\n");
	}

	/*
	 * ---------------------------------------------------------------
	 * STEP 4 / STEP 5 -- the two connect attempts, same credentials,
	 * back to back. See conntwice_attempt() and the file header's THE
	 * ONE UNPROVEN LINK section for what each one is exercising.
	 * ---------------------------------------------------------------
	 */
	alp_cc3501e_wifi_status_t st1        = { 0 };
	alp_status_t              st1_status = conntwice_attempt(&fw, 1u, &st1);

	alp_cc3501e_wifi_status_t st2        = { 0 };
	alp_status_t              st2_status = conntwice_attempt(&fw, 2u, &st2);

	/*
	 * ---------------------------------------------------------------
	 * STEP 6 -- the plain reading. Prints the pair and what the pair
	 * means, per the three cases the file header names; nothing beyond
	 * that is concluded here (see the file header's closing note).
	 * ---------------------------------------------------------------
	 */
	printk("\nSTEP 6: the reading\n");
	printk("  attempt 1: state=%s fail_reason=%s\n",
	       (st1_status == ALP_OK) ? conntwice_state_name(st1.state) : "UNREAD",
	       (st1_status == ALP_OK) ? conntwice_fail_name(st1.fail_reason) : "UNREAD");
	printk("  attempt 2: state=%s fail_reason=%s\n",
	       (st2_status == ALP_OK) ? conntwice_state_name(st2.state) : "UNREAD",
	       (st2_status == ALP_OK) ? conntwice_fail_name(st2.fail_reason) : "UNREAD");

	if (st1_status != ALP_OK || st2_status != ALP_OK) {
		printk("  VERDICT: at least one WIFI_STATUS read failed -- the pair above is"
		       " incomplete, so no verdict can be read off it this run.\n");
	} else if (st1.state == ALP_CC3501E_WIFI_CONNECTED) {
		printk("  VERDICT: attempt one SUCCEEDED -- this run says nothing about the"
		       " disconnect-bit hypothesis. There was no failure on attempt one to leave"
		       " the bit set behind in the first place.\n");
	} else if (st1.state != ALP_CC3501E_WIFI_CONN_FAILED) {
		printk("  VERDICT: attempt one did not reach a terminal CONNECTED/CONN_FAILED"
		       " state within its own %u ms budget (state=%s) -- cannot evaluate the"
		       " hypothesis this run.\n",
		       (unsigned)CONNTWICE_CONNECT_TIMEOUT_MS,
		       conntwice_state_name(st1.state));
	} else if (st2.state == ALP_CC3501E_WIFI_CONNECTED) {
		printk("  VERDICT: attempt one FAILED (fail_reason=%s) but attempt two SUCCEEDED"
		       " -- the second connect was not blocked, whatever the disconnect bit's"
		       " state actually was. This neither confirms nor refutes the hypothesis by"
		       " itself; printing the raw pair above for the record.\n",
		       conntwice_fail_name(st1.fail_reason));
	} else if (st2.state != ALP_CC3501E_WIFI_CONN_FAILED) {
		printk("  VERDICT: attempt one FAILED (fail_reason=%s) but attempt two did not"
		       " reach a terminal state within its own %u ms budget (state=%s) -- cannot"
		       " classify the pair this run.\n",
		       conntwice_fail_name(st1.fail_reason),
		       (unsigned)CONNTWICE_CONNECT_TIMEOUT_MS,
		       conntwice_state_name(st2.state));
	} else if (st1.fail_reason == ALP_CC3501E_WIFI_FAIL_TIMEOUT &&
	           st2.fail_reason == ALP_CC3501E_WIFI_FAIL_KICK) {
		printk("  VERDICT: CONFIRMED. Attempt one timed out (FAIL_TIMEOUT) and attempt two"
		       " died at the kick (FAIL_KICK) with the identical credentials -- the"
		       " disconnect-in-progress bit stuck across the two attempts, exactly the"
		       " predicted pattern (see this file's header, THE CHAIN THIS APP TESTS).\n");
	} else if (st1.fail_reason == st2.fail_reason) {
		printk("  VERDICT: DEAD. Both attempts failed with the SAME reason (%s) -- the bit"
		       " does not stick across a station-never-associated disconnect; the chain"
		       " this app tests does not bite here.\n",
		       conntwice_fail_name(st1.fail_reason));
	} else {
		printk("  VERDICT: neither predicted pattern -- attempt one failed with %s,"
		       " attempt two with %s. Not TIMEOUT-then-KICK, not identical. Printing the"
		       " pair for manual review; no verdict beyond it is claimed here.\n",
		       conntwice_fail_name(st1.fail_reason),
		       conntwice_fail_name(st2.fail_reason));
	}

	return 0;
}
```
